AUTOSAR XML (schema 4-2-1)
standard types defined: boolean, float32, uint8, boolean_CompuMethod, boolean_DataConstr, float32_DataConstr, uint8_DataConstr
package /ComponentTypes
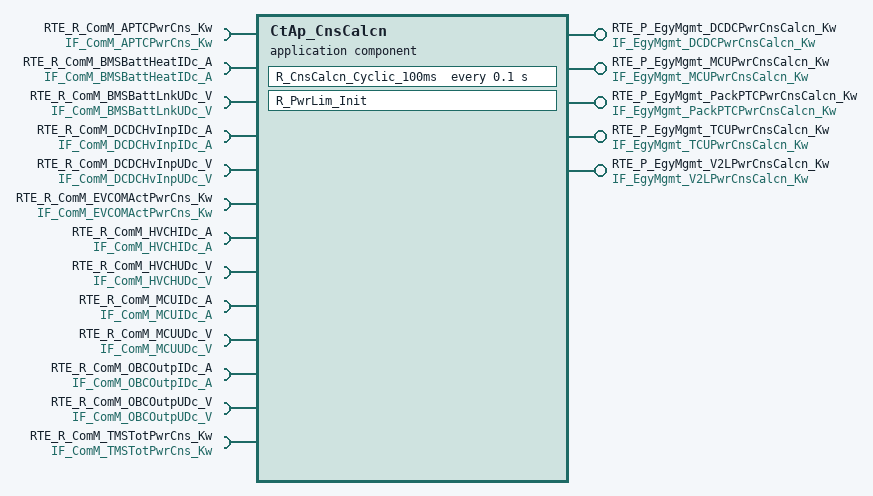
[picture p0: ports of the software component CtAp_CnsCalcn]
  application sw component type CtAp_CnsCalcn
    5 x provide port:
      RTE_P_EgyMgmt_DCDCPwrCnsCalcn_Kw: nonqueued-sender-com-spec{data-element=tec_EgyMgmt_DCDCPwrCnsCalcn_Kw, init-value=0}, provided-interface=IF_EgyMgmt_DCDCPwrCnsCalcn_Kw
      RTE_P_EgyMgmt_MCUPwrCnsCalcn_Kw: nonqueued-sender-com-spec{data-element=tec_EgyMgmt_MCUPwrCnsCalcn_Kw, init-value=0}, provided-interface=IF_EgyMgmt_MCUPwrCnsCalcn_Kw
      RTE_P_EgyMgmt_PackPTCPwrCnsCalcn_Kw: nonqueued-sender-com-spec{data-element=tec_EgyMgmt_PackPTCPwrCnsCalcn_Kw, init-value=0}, provided-interface=IF_EgyMgmt_PackPTCPwrCnsCalcn_Kw
      RTE_P_EgyMgmt_TCUPwrCnsCalcn_Kw: nonqueued-sender-com-spec{data-element=tec_EgyMgmt_TCUPwrCnsCalcn_Kw, init-value=0}, provided-interface=IF_EgyMgmt_TCUPwrCnsCalcn_Kw
      RTE_P_EgyMgmt_V2LPwrCnsCalcn_Kw: nonqueued-sender-com-spec{data-element=IF_EgyMgmt_V2LPwrCnsCalcn_Kw, init-value=0}, provided-interface=IF_EgyMgmt_V2LPwrCnsCalcn_Kw
    13 x require port:
      RTE_R_ComM_APTCPwrCns_Kw: nonqueued-receiver-com-spec{data-element=tec_ComM_APTCPwrCns_Kw, filter=data-filter-type=ALWAYS, init-value=0}, required-interface=IF_ComM_APTCPwrCns_Kw
      RTE_R_ComM_BMSBattHeatIDc_A: nonqueued-receiver-com-spec{data-element=tec_ComM_BMSBattHeatIDc_A, filter=data-filter-type=ALWAYS, init-value=0}, required-interface=IF_ComM_BMSBattHeatIDc_A
      RTE_R_ComM_BMSBattLnkUDc_V: nonqueued-receiver-com-spec{data-element=tec_ComM_BMSBattLnkUDc_V, filter=data-filter-type=ALWAYS, init-value=0}, required-interface=IF_ComM_BMSBattLnkUDc_V
      RTE_R_ComM_DCDCHvInpIDc_A: nonqueued-receiver-com-spec{data-element=tec_ComM_DCDCHvInpIDc_A, filter=data-filter-type=ALWAYS, init-value=0}, required-interface=IF_ComM_DCDCHvInpIDc_A
      RTE_R_ComM_DCDCHvInpUDc_V: nonqueued-receiver-com-spec{data-element=tec_ComM_DCDCHvInpUDc_V, filter=data-filter-type=ALWAYS, init-value=0}, required-interface=IF_ComM_DCDCHvInpUDc_V
      RTE_R_ComM_EVCOMActPwrCns_Kw: nonqueued-receiver-com-spec{data-element=tec_ComM_EVCOMActPwrCns_Kw, filter=data-filter-type=ALWAYS, init-value=0}, required-interface=IF_ComM_EVCOMActPwrCns_Kw
      RTE_R_ComM_HVCHIDc_A: nonqueued-receiver-com-spec{data-element=tec_ComM_HVCHIDc_A, filter=data-filter-type=ALWAYS, init-value=0}, required-interface=IF_ComM_HVCHIDc_A
      RTE_R_ComM_HVCHUDc_V: nonqueued-receiver-com-spec{data-element=tec_ComM_HVCHUDc_V, filter=data-filter-type=ALWAYS, init-value=0}, required-interface=IF_ComM_HVCHUDc_V
      RTE_R_ComM_MCUIDc_A: nonqueued-receiver-com-spec{data-element=tec_ComM_MCUIDc_A, filter=data-filter-type=ALWAYS, init-value=0}, required-interface=IF_ComM_MCUIDc_A
      RTE_R_ComM_MCUUDc_V: nonqueued-receiver-com-spec{data-element=tec_ComM_MCUUDc_V, filter=data-filter-type=ALWAYS, init-value=0}, required-interface=IF_ComM_MCUUDc_V
      RTE_R_ComM_OBCOutpIDc_A: nonqueued-receiver-com-spec{data-element=tec_ComM_OBCOutpIDc_A, filter=data-filter-type=ALWAYS, init-value=0}, required-interface=IF_ComM_OBCOutpIDc_A
      RTE_R_ComM_OBCOutpUDc_V: nonqueued-receiver-com-spec{data-element=tec_ComM_OBCOutpUDc_V, filter=data-filter-type=ALWAYS, init-value=0}, required-interface=IF_ComM_OBCOutpUDc_V
      RTE_R_ComM_TMSTotPwrCns_Kw: nonqueued-receiver-com-spec{data-element=tec_ComM_TMSTotPwrCns_Kw, filter=data-filter-type=ALWAYS, init-value=0}, required-interface=IF_ComM_TMSTotPwrCns_Kw
    behavior CtAp_CnsCalcn_InternalBehavior
      timing event TMT_R_CnsCalcn_Cyclic_100ms: start-on-event=R_CnsCalcn_Cyclic_100ms, period=0.1
      init event CtAp_PwrLim_InitEvent: start-on-event=CtAp_CnsCalcn_InternalBehavior/R_PwrLim_Init
      runnable R_CnsCalcn_Cyclic_100ms
        data-receive-point-by-arguments:
          13 x access:
            REC_RTE_R_ComM_APTCPwrCns_Kw_tec_ComM_APTCPwrCns_Kw: accessed-variable=RTE_R_ComM_APTCPwrCns_Kw.tec_ComM_APTCPwrCns_Kw
            REC_RTE_R_ComM_BMSBattHeatIDc_A_tec_ComM_BMSBattHeatIDc_A: accessed-variable=RTE_R_ComM_BMSBattHeatIDc_A.tec_ComM_BMSBattHeatIDc_A
            REC_RTE_R_ComM_BMSBattLnkUDc_V_tec_ComM_BMSBattLnkUDc_V: accessed-variable=RTE_R_ComM_BMSBattLnkUDc_V.tec_ComM_BMSBattLnkUDc_V
            REC_RTE_R_ComM_DCDCHvInpIDc_A_tec_ComM_DCDCHvInpIDc_A: accessed-variable=RTE_R_ComM_DCDCHvInpIDc_A.tec_ComM_DCDCHvInpIDc_A
            REC_RTE_R_ComM_DCDCHvInpUDc_V_tec_ComM_DCDCHvInpUDc_V: accessed-variable=RTE_R_ComM_DCDCHvInpUDc_V.tec_ComM_DCDCHvInpUDc_V
            REC_RTE_R_ComM_EVCOMActPwrCns_Kw_tec_ComM_EVCOMActPwrCns_Kw: accessed-variable=RTE_R_ComM_EVCOMActPwrCns_Kw.tec_ComM_EVCOMActPwrCns_Kw
            REC_RTE_R_ComM_HVCHIDc_A_tec_ComM_HVCHIDc_A: accessed-variable=RTE_R_ComM_HVCHIDc_A.tec_ComM_HVCHIDc_A
            REC_RTE_R_ComM_HVCHUDc_V_tec_ComM_HVCHUDc_V: accessed-variable=RTE_R_ComM_HVCHUDc_V.tec_ComM_HVCHUDc_V
            REC_RTE_R_ComM_MCUIDc_A_tec_ComM_MCUIDc_A: accessed-variable=RTE_R_ComM_MCUIDc_A.tec_ComM_MCUIDc_A
            REC_RTE_R_ComM_MCUUDc_V_tec_ComM_MCUUDc_V: accessed-variable=RTE_R_ComM_MCUUDc_V.tec_ComM_MCUUDc_V
            REC_RTE_R_ComM_OBCOutpIDc_A_tec_ComM_OBCOutpIDc_A: accessed-variable=RTE_R_ComM_OBCOutpIDc_A.tec_ComM_OBCOutpIDc_A
            REC_RTE_R_ComM_OBCOutpUDc_V_tec_ComM_OBCOutpUDc_V: accessed-variable=RTE_R_ComM_OBCOutpUDc_V.tec_ComM_OBCOutpUDc_V
            REC_RTE_R_ComM_TMSTotPwrCns_Kw_tec_ComM_TMSTotPwrCns_Kw: accessed-variable=RTE_R_ComM_TMSTotPwrCns_Kw.tec_ComM_TMSTotPwrCns_Kw
        data-send-points:
          5 x access:
            SEND_RTE_P_EgyMgmt_DCDCPwrCnsCalcn_Kw_tec_EgyMgmt_DCDCPwrCnsCalcn_Kw: accessed-variable=RTE_P_EgyMgmt_DCDCPwrCnsCalcn_Kw.tec_EgyMgmt_DCDCPwrCnsCalcn_Kw
            SEND_RTE_P_EgyMgmt_MCUPwrCnsCalcn_Kw_tec_EgyMgmt_MCUPwrCnsCalcn_Kw: accessed-variable=RTE_P_EgyMgmt_MCUPwrCnsCalcn_Kw.tec_EgyMgmt_MCUPwrCnsCalcn_Kw
            SEND_RTE_P_EgyMgmt_PackPTCPwrCnsCalcn_Kw_tec_EgyMgmt_PackPTCPwrCnsCalcn_Kw: accessed-variable=RTE_P_EgyMgmt_PackPTCPwrCnsCalcn_Kw.tec_EgyMgmt_PackPTCPwrCnsCalcn_Kw
            SEND_RTE_P_EgyMgmt_TCUPwrCnsCalcn_Kw_tec_EgyMgmt_TCUPwrCnsCalcn_Kw: accessed-variable=RTE_P_EgyMgmt_TCUPwrCnsCalcn_Kw.tec_EgyMgmt_TCUPwrCnsCalcn_Kw
            SEND_RTE_P_EgyMgmt_V2LPwrCnsCalcn_Kw_IF_EgyMgmt_V2LPwrCnsCalcn_Kw: accessed-variable=RTE_P_EgyMgmt_V2LPwrCnsCalcn_Kw.IF_EgyMgmt_V2LPwrCnsCalcn_Kw
      runnable R_PwrLim_Init
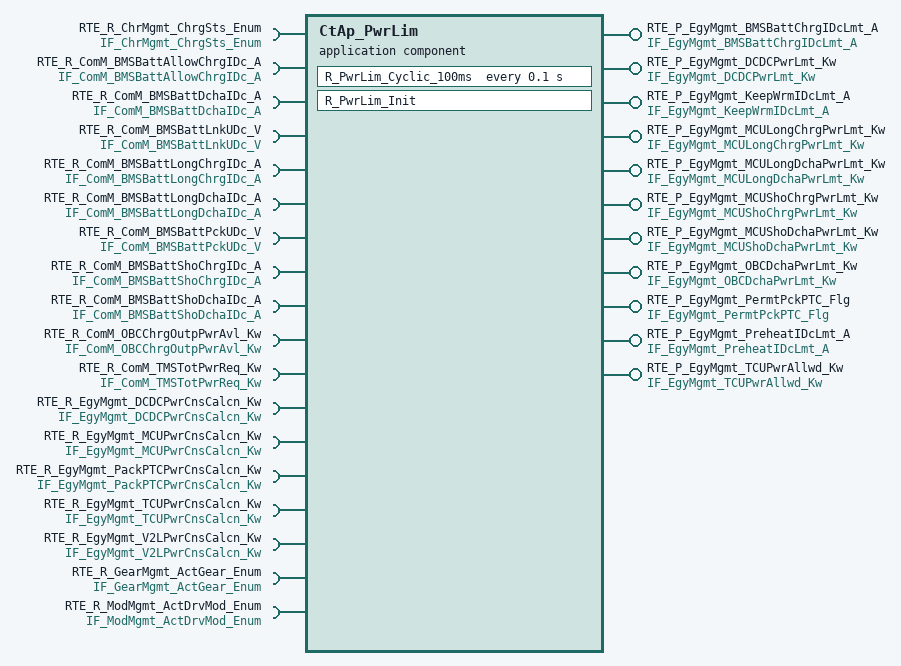
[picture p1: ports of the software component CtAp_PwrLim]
  application sw component type CtAp_PwrLim
    11 x provide port:
      RTE_P_EgyMgmt_BMSBattChrgIDcLmt_A: nonqueued-sender-com-spec{data-element=tec_EgyMgmt_BMSBattChrgIDcLmt_A, init-value=0}, provided-interface=IF_EgyMgmt_BMSBattChrgIDcLmt_A
      RTE_P_EgyMgmt_DCDCPwrLmt_Kw: nonqueued-sender-com-spec{data-element=tec_EgyMgmt_DCDCPwrLmt_Kw, init-value=0}, provided-interface=IF_EgyMgmt_DCDCPwrLmt_Kw
      RTE_P_EgyMgmt_KeepWrmIDcLmt_A: nonqueued-sender-com-spec{data-element=tec_EgyMgmt_KeepWrmIDcLmt_A, init-value=0}, provided-interface=IF_EgyMgmt_KeepWrmIDcLmt_A
      RTE_P_EgyMgmt_MCULongChrgPwrLmt_Kw: nonqueued-sender-com-spec{data-element=tec_EgyMgmt_MCULongChrgPwrLmt_Kw, init-value=0}, provided-interface=IF_EgyMgmt_MCULongChrgPwrLmt_Kw
      RTE_P_EgyMgmt_MCULongDchaPwrLmt_Kw: nonqueued-sender-com-spec{data-element=tec_EgyMgmt_MCULongDchaPwrLmt_Kw, init-value=0}, provided-interface=IF_EgyMgmt_MCULongDchaPwrLmt_Kw
      RTE_P_EgyMgmt_MCUShoChrgPwrLmt_Kw: nonqueued-sender-com-spec{data-element=tec_EgyMgmt_MCUShoChrgPwrLmt_Kw, init-value=0}, provided-interface=IF_EgyMgmt_MCUShoChrgPwrLmt_Kw
      RTE_P_EgyMgmt_MCUShoDchaPwrLmt_Kw: nonqueued-sender-com-spec{data-element=tec_EgyMgmt_MCUShoDchaPwrLmt_Kw, init-value=0}, provided-interface=IF_EgyMgmt_MCUShoDchaPwrLmt_Kw
      RTE_P_EgyMgmt_OBCDchaPwrLmt_Kw: nonqueued-sender-com-spec{data-element=tec_EgyMgmt_OBCDchaPwrLmt_Kw, init-value=0}, provided-interface=IF_EgyMgmt_OBCDchaPwrLmt_Kw
      RTE_P_EgyMgmt_PermtPckPTC_Flg: nonqueued-sender-com-spec{data-element=tec_EgyMgmt_PermtPckPTC_Flg, init-value=0}, provided-interface=IF_EgyMgmt_PermtPckPTC_Flg
      RTE_P_EgyMgmt_PreheatIDcLmt_A: nonqueued-sender-com-spec{data-element=tec_EgyMgmt_PreheatIDcLmt_A, init-value=0}, provided-interface=IF_EgyMgmt_PreheatIDcLmt_A
      RTE_P_EgyMgmt_TCUPwrAllwd_Kw: nonqueued-sender-com-spec{data-element=tec_EgyMgmt_TCUPwrAllwd_Kw, init-value=0}, provided-interface=IF_EgyMgmt_TCUPwrAllwd_Kw
    18 x require port:
      RTE_R_ChrMgmt_ChrgSts_Enum: nonqueued-receiver-com-spec{data-element=tec_ChrMgmt_ChrgSts_Enum, filter=data-filter-type=ALWAYS, init-value=0}, required-interface=IF_ChrMgmt_ChrgSts_Enum
      RTE_R_ComM_BMSBattAllowChrgIDc_A: nonqueued-receiver-com-spec{data-element=tec_ComM_BMSBattAllowChrgIDc_A, filter=data-filter-type=ALWAYS, init-value=0}, required-interface=IF_ComM_BMSBattAllowChrgIDc_A
      RTE_R_ComM_BMSBattDchaIDc_A: nonqueued-receiver-com-spec{data-element=tec_ComM_BMSBattDchaIDc_A, filter=data-filter-type=ALWAYS, init-value=0}, required-interface=IF_ComM_BMSBattDchaIDc_A
      RTE_R_ComM_BMSBattLnkUDc_V: nonqueued-receiver-com-spec{data-element=tec_ComM_BMSBattLnkUDc_V, filter=data-filter-type=ALWAYS, init-value=0}, required-interface=IF_ComM_BMSBattLnkUDc_V
      RTE_R_ComM_BMSBattLongChrgIDc_A: nonqueued-receiver-com-spec{data-element=tec_ComM_BMSBattLongChrgIDc_A, filter=data-filter-type=ALWAYS, init-value=0}, required-interface=IF_ComM_BMSBattLongChrgIDc_A
      RTE_R_ComM_BMSBattLongDchaIDc_A: nonqueued-receiver-com-spec{data-element=tec_ComM_BMSBattLongDchaIDc_A, filter=data-filter-type=ALWAYS, init-value=0}, required-interface=IF_ComM_BMSBattLongDchaIDc_A
      RTE_R_ComM_BMSBattPckUDc_V: nonqueued-receiver-com-spec{data-element=tec_ComM_BMSBattPckUDc_V, filter=data-filter-type=ALWAYS, init-value=0}, required-interface=IF_ComM_BMSBattPckUDc_V
      RTE_R_ComM_BMSBattShoChrgIDc_A: nonqueued-receiver-com-spec{data-element=tec_ComM_BMSBattShoChrgIDc_A, filter=data-filter-type=ALWAYS, init-value=0}, required-interface=IF_ComM_BMSBattShoChrgIDc_A
      RTE_R_ComM_BMSBattShoDchaIDc_A: nonqueued-receiver-com-spec{data-element=tec_ComM_BMSBattShoDchaIDc_A, filter=data-filter-type=ALWAYS, init-value=0}, required-interface=IF_ComM_BMSBattShoDchaIDc_A
      RTE_R_ComM_OBCChrgOutpPwrAvl_Kw: nonqueued-receiver-com-spec{data-element=tec_ComM_OBCChrgOutpPwrAvl_Kw, filter=data-filter-type=ALWAYS, init-value=0}, required-interface=IF_ComM_OBCChrgOutpPwrAvl_Kw
      RTE_R_ComM_TMSTotPwrReq_Kw: nonqueued-receiver-com-spec{data-element=tec_ComM_TMSTotPwrReq_Kw, filter=data-filter-type=ALWAYS, init-value=0}, required-interface=IF_ComM_TMSTotPwrReq_Kw
      RTE_R_EgyMgmt_DCDCPwrCnsCalcn_Kw: nonqueued-receiver-com-spec{data-element=tec_EgyMgmt_DCDCPwrCnsCalcn_Kw, filter=data-filter-type=ALWAYS, init-value=0}, required-interface=IF_EgyMgmt_DCDCPwrCnsCalcn_Kw
      RTE_R_EgyMgmt_MCUPwrCnsCalcn_Kw: nonqueued-receiver-com-spec{data-element=tec_EgyMgmt_MCUPwrCnsCalcn_Kw, filter=data-filter-type=ALWAYS, init-value=0}, required-interface=IF_EgyMgmt_MCUPwrCnsCalcn_Kw
      RTE_R_EgyMgmt_PackPTCPwrCnsCalcn_Kw: nonqueued-receiver-com-spec{data-element=tec_EgyMgmt_PackPTCPwrCnsCalcn_Kw, filter=data-filter-type=ALWAYS, init-value=0}, required-interface=IF_EgyMgmt_PackPTCPwrCnsCalcn_Kw
      RTE_R_EgyMgmt_TCUPwrCnsCalcn_Kw: nonqueued-receiver-com-spec{data-element=tec_EgyMgmt_TCUPwrCnsCalcn_Kw, filter=data-filter-type=ALWAYS, init-value=0}, required-interface=IF_EgyMgmt_TCUPwrCnsCalcn_Kw
      RTE_R_EgyMgmt_V2LPwrCnsCalcn_Kw: nonqueued-receiver-com-spec{data-element=IF_EgyMgmt_V2LPwrCnsCalcn_Kw, filter=data-filter-type=ALWAYS, init-value=0}, required-interface=IF_EgyMgmt_V2LPwrCnsCalcn_Kw
      RTE_R_GearMgmt_ActGear_Enum: nonqueued-receiver-com-spec{data-element=tec_GearMgmt_ActGear_Enum, filter=data-filter-type=ALWAYS, init-value=0}, required-interface=IF_GearMgmt_ActGear_Enum
      RTE_R_ModMgmt_ActDrvMod_Enum: nonqueued-receiver-com-spec{data-element=tec_ModMgmt_ActDrvMod_Enum, filter=data-filter-type=ALWAYS, init-value=0}, required-interface=IF_ModMgmt_ActDrvMod_Enum
    behavior CtAp_PwrLim_InternalBehavior
      timing event TMT_R_PwrLim_Cyclic_100ms: start-on-event=R_PwrLim_Cyclic_100ms, period=0.1
      init event CtAp_PwrLim_InitEvent: start-on-event=CtAp_PwrLim_InternalBehavior/R_PwrLim_Init
      runnable R_PwrLim_Cyclic_100ms
        data-receive-point-by-arguments:
          18 x access:
            REC_RTE_R_ChrMgmt_ChrgSts_Enum_tec_ChrMgmt_ChrgSts_Enum: accessed-variable=RTE_R_ChrMgmt_ChrgSts_Enum.tec_ChrMgmt_ChrgSts_Enum
            REC_RTE_R_ComM_BMSBattAllowChrgIDc_A_tec_ComM_BMSBattAllowChrgIDc_A: accessed-variable=RTE_R_ComM_BMSBattAllowChrgIDc_A.tec_ComM_BMSBattAllowChrgIDc_A
            REC_RTE_R_ComM_BMSBattDchaIDc_A_tec_ComM_BMSBattDchaIDc_A: accessed-variable=RTE_R_ComM_BMSBattDchaIDc_A.tec_ComM_BMSBattDchaIDc_A
            REC_RTE_R_ComM_BMSBattLnkUDc_V_tec_ComM_BMSBattLnkUDc_V: accessed-variable=RTE_R_ComM_BMSBattLnkUDc_V.tec_ComM_BMSBattLnkUDc_V
            REC_RTE_R_ComM_BMSBattLongChrgIDc_A_tec_ComM_BMSBattLongChrgIDc_A: accessed-variable=RTE_R_ComM_BMSBattLongChrgIDc_A.tec_ComM_BMSBattLongChrgIDc_A
            REC_RTE_R_ComM_BMSBattLongDchaIDc_A_tec_ComM_BMSBattLongDchaIDc_A: accessed-variable=RTE_R_ComM_BMSBattLongDchaIDc_A.tec_ComM_BMSBattLongDchaIDc_A
            REC_RTE_R_ComM_BMSBattPckUDc_V_tec_ComM_BMSBattPckUDc_V: accessed-variable=RTE_R_ComM_BMSBattPckUDc_V.tec_ComM_BMSBattPckUDc_V
            REC_RTE_R_ComM_BMSBattShoChrgIDc_A_tec_ComM_BMSBattShoChrgIDc_A: accessed-variable=RTE_R_ComM_BMSBattShoChrgIDc_A.tec_ComM_BMSBattShoChrgIDc_A
            REC_RTE_R_ComM_BMSBattShoDchaIDc_A_tec_ComM_BMSBattShoDchaIDc_A: accessed-variable=RTE_R_ComM_BMSBattShoDchaIDc_A.tec_ComM_BMSBattShoDchaIDc_A
            REC_RTE_R_ComM_OBCChrgOutpPwrAvl_Kw_tec_ComM_OBCChrgOutpPwrAvl_Kw: accessed-variable=RTE_R_ComM_OBCChrgOutpPwrAvl_Kw.tec_ComM_OBCChrgOutpPwrAvl_Kw
            REC_RTE_R_ComM_TMSTotPwrReq_Kw_tec_ComM_TMSTotPwrReq_Kw: accessed-variable=RTE_R_ComM_TMSTotPwrReq_Kw.tec_ComM_TMSTotPwrReq_Kw
            REC_RTE_R_EgyMgmt_DCDCPwrCnsCalcn_Kw_tec_EgyMgmt_DCDCPwrCnsCalcn_Kw: accessed-variable=RTE_R_EgyMgmt_DCDCPwrCnsCalcn_Kw.tec_EgyMgmt_DCDCPwrCnsCalcn_Kw
            REC_RTE_R_EgyMgmt_MCUPwrCnsCalcn_Kw_tec_EgyMgmt_MCUPwrCnsCalcn_Kw: accessed-variable=RTE_R_EgyMgmt_MCUPwrCnsCalcn_Kw.tec_EgyMgmt_MCUPwrCnsCalcn_Kw
            REC_RTE_R_EgyMgmt_PackPTCPwrCnsCalcn_Kw_tec_EgyMgmt_PackPTCPwrCnsCalcn_Kw: accessed-variable=RTE_R_EgyMgmt_PackPTCPwrCnsCalcn_Kw.tec_EgyMgmt_PackPTCPwrCnsCalcn_Kw
            REC_RTE_R_EgyMgmt_TCUPwrCnsCalcn_Kw_tec_EgyMgmt_TCUPwrCnsCalcn_Kw: accessed-variable=RTE_R_EgyMgmt_TCUPwrCnsCalcn_Kw.tec_EgyMgmt_TCUPwrCnsCalcn_Kw
            REC_RTE_R_EgyMgmt_V2LPwrCnsCalcn_Kw_IF_EgyMgmt_V2LPwrCnsCalcn_Kw: accessed-variable=RTE_R_EgyMgmt_V2LPwrCnsCalcn_Kw.IF_EgyMgmt_V2LPwrCnsCalcn_Kw
            REC_RTE_R_GearMgmt_ActGear_Enum_tec_GearMgmt_ActGear_Enum: accessed-variable=RTE_R_GearMgmt_ActGear_Enum.tec_GearMgmt_ActGear_Enum
            REC_RTE_R_ModMgmt_ActDrvMod_Enum_tec_ModMgmt_ActDrvMod_Enum: accessed-variable=RTE_R_ModMgmt_ActDrvMod_Enum.tec_ModMgmt_ActDrvMod_Enum
        data-send-points:
          11 x access:
            SEND_RTE_P_EgyMgmt_BMSBattChrgIDcLmt_A_tec_EgyMgmt_BMSBattChrgIDcLmt_A: accessed-variable=RTE_P_EgyMgmt_BMSBattChrgIDcLmt_A.tec_EgyMgmt_BMSBattChrgIDcLmt_A
            SEND_RTE_P_EgyMgmt_DCDCPwrLmt_Kw_tec_EgyMgmt_DCDCPwrLmt_Kw: accessed-variable=RTE_P_EgyMgmt_DCDCPwrLmt_Kw.tec_EgyMgmt_DCDCPwrLmt_Kw
            SEND_RTE_P_EgyMgmt_KeepWrmIDcLmt_A_tec_EgyMgmt_KeepWrmIDcLmt_A: accessed-variable=RTE_P_EgyMgmt_KeepWrmIDcLmt_A.tec_EgyMgmt_KeepWrmIDcLmt_A
            SEND_RTE_P_EgyMgmt_MCULongChrgPwrLmt_Kw_tec_EgyMgmt_MCULongChrgPwrLmt_Kw: accessed-variable=RTE_P_EgyMgmt_MCULongChrgPwrLmt_Kw.tec_EgyMgmt_MCULongChrgPwrLmt_Kw
            SEND_RTE_P_EgyMgmt_MCULongDchaPwrLmt_Kw_tec_EgyMgmt_MCULongDchaPwrLmt_Kw: accessed-variable=RTE_P_EgyMgmt_MCULongDchaPwrLmt_Kw.tec_EgyMgmt_MCULongDchaPwrLmt_Kw
            SEND_RTE_P_EgyMgmt_MCUShoChrgPwrLmt_Kw_tec_EgyMgmt_MCUShoChrgPwrLmt_Kw: accessed-variable=RTE_P_EgyMgmt_MCUShoChrgPwrLmt_Kw.tec_EgyMgmt_MCUShoChrgPwrLmt_Kw
            SEND_RTE_P_EgyMgmt_MCUShoDchaPwrLmt_Kw_tec_EgyMgmt_MCUShoDchaPwrLmt_Kw: accessed-variable=RTE_P_EgyMgmt_MCUShoDchaPwrLmt_Kw.tec_EgyMgmt_MCUShoDchaPwrLmt_Kw
            SEND_RTE_P_EgyMgmt_OBCDchaPwrLmt_Kw_tec_EgyMgmt_OBCDchaPwrLmt_Kw: accessed-variable=RTE_P_EgyMgmt_OBCDchaPwrLmt_Kw.tec_EgyMgmt_OBCDchaPwrLmt_Kw
            SEND_RTE_P_EgyMgmt_PermtPckPTC_Flg_tec_EgyMgmt_PermtPckPTC_Flg: accessed-variable=RTE_P_EgyMgmt_PermtPckPTC_Flg.tec_EgyMgmt_PermtPckPTC_Flg
            SEND_RTE_P_EgyMgmt_PreheatIDcLmt_A_tec_EgyMgmt_PreheatIDcLmt_A: accessed-variable=RTE_P_EgyMgmt_PreheatIDcLmt_A.tec_EgyMgmt_PreheatIDcLmt_A
            SEND_RTE_P_EgyMgmt_TCUPwrAllwd_Kw_tec_EgyMgmt_TCUPwrAllwd_Kw: accessed-variable=RTE_P_EgyMgmt_TCUPwrAllwd_Kw.tec_EgyMgmt_TCUPwrAllwd_Kw
      runnable R_PwrLim_Init
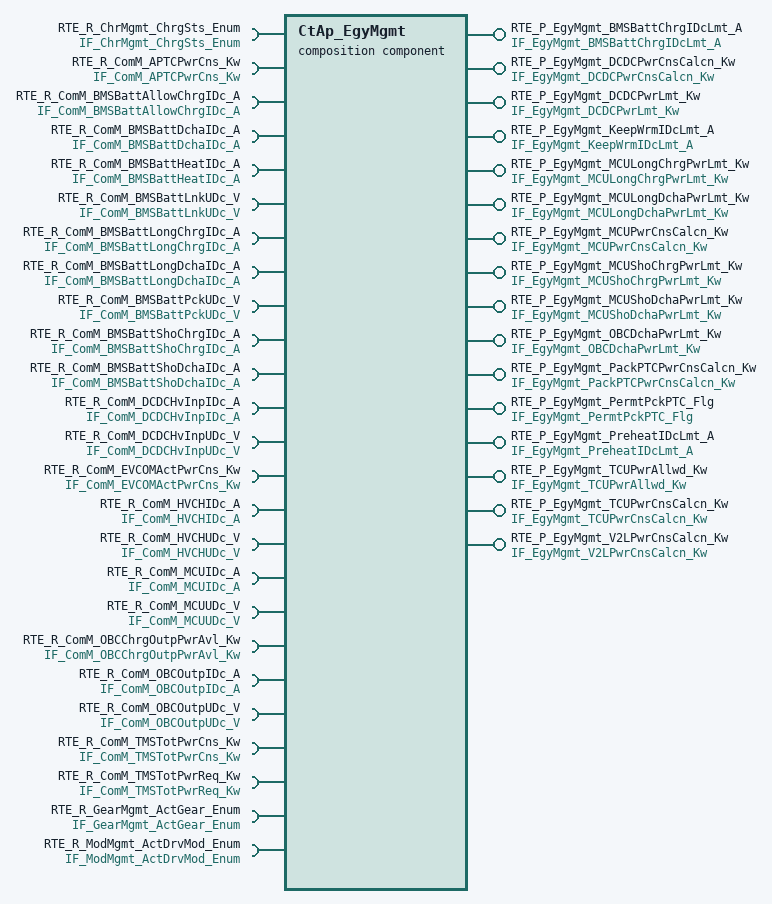
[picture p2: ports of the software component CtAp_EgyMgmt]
  composition sw component type CtAp_EgyMgmt
    16 x provide port:
      RTE_P_EgyMgmt_BMSBattChrgIDcLmt_A: nonqueued-sender-com-spec{data-element=tec_EgyMgmt_BMSBattChrgIDcLmt_A, init-value=0}, provided-interface=IF_EgyMgmt_BMSBattChrgIDcLmt_A
      RTE_P_EgyMgmt_DCDCPwrCnsCalcn_Kw: nonqueued-sender-com-spec{data-element=tec_EgyMgmt_DCDCPwrCnsCalcn_Kw, init-value=0}, provided-interface=IF_EgyMgmt_DCDCPwrCnsCalcn_Kw
      RTE_P_EgyMgmt_DCDCPwrLmt_Kw: nonqueued-sender-com-spec{data-element=tec_EgyMgmt_DCDCPwrLmt_Kw, init-value=0}, provided-interface=IF_EgyMgmt_DCDCPwrLmt_Kw
      RTE_P_EgyMgmt_KeepWrmIDcLmt_A: nonqueued-sender-com-spec{data-element=tec_EgyMgmt_KeepWrmIDcLmt_A, init-value=0}, provided-interface=IF_EgyMgmt_KeepWrmIDcLmt_A
      RTE_P_EgyMgmt_MCULongChrgPwrLmt_Kw: nonqueued-sender-com-spec{data-element=tec_EgyMgmt_MCULongChrgPwrLmt_Kw, init-value=0}, provided-interface=IF_EgyMgmt_MCULongChrgPwrLmt_Kw
      RTE_P_EgyMgmt_MCULongDchaPwrLmt_Kw: nonqueued-sender-com-spec{data-element=tec_EgyMgmt_MCULongDchaPwrLmt_Kw, init-value=0}, provided-interface=IF_EgyMgmt_MCULongDchaPwrLmt_Kw
      RTE_P_EgyMgmt_MCUPwrCnsCalcn_Kw: nonqueued-sender-com-spec{data-element=tec_EgyMgmt_MCUPwrCnsCalcn_Kw, init-value=0}, provided-interface=IF_EgyMgmt_MCUPwrCnsCalcn_Kw
      RTE_P_EgyMgmt_MCUShoChrgPwrLmt_Kw: nonqueued-sender-com-spec{data-element=tec_EgyMgmt_MCUShoChrgPwrLmt_Kw, init-value=0}, provided-interface=IF_EgyMgmt_MCUShoChrgPwrLmt_Kw
      RTE_P_EgyMgmt_MCUShoDchaPwrLmt_Kw: nonqueued-sender-com-spec{data-element=tec_EgyMgmt_MCUShoDchaPwrLmt_Kw, init-value=0}, provided-interface=IF_EgyMgmt_MCUShoDchaPwrLmt_Kw
      RTE_P_EgyMgmt_OBCDchaPwrLmt_Kw: nonqueued-sender-com-spec{data-element=tec_EgyMgmt_OBCDchaPwrLmt_Kw, init-value=0}, provided-interface=IF_EgyMgmt_OBCDchaPwrLmt_Kw
      RTE_P_EgyMgmt_PackPTCPwrCnsCalcn_Kw: nonqueued-sender-com-spec{data-element=tec_EgyMgmt_PackPTCPwrCnsCalcn_Kw, init-value=0}, provided-interface=IF_EgyMgmt_PackPTCPwrCnsCalcn_Kw
      RTE_P_EgyMgmt_PermtPckPTC_Flg: nonqueued-sender-com-spec{data-element=tec_EgyMgmt_PermtPckPTC_Flg, init-value=0}, provided-interface=IF_EgyMgmt_PermtPckPTC_Flg
      RTE_P_EgyMgmt_PreheatIDcLmt_A: nonqueued-sender-com-spec{data-element=tec_EgyMgmt_PreheatIDcLmt_A, init-value=0}, provided-interface=IF_EgyMgmt_PreheatIDcLmt_A
      RTE_P_EgyMgmt_TCUPwrAllwd_Kw: nonqueued-sender-com-spec{data-element=tec_EgyMgmt_TCUPwrAllwd_Kw, init-value=0}, provided-interface=IF_EgyMgmt_TCUPwrAllwd_Kw
      RTE_P_EgyMgmt_TCUPwrCnsCalcn_Kw: nonqueued-sender-com-spec{data-element=tec_EgyMgmt_TCUPwrCnsCalcn_Kw, init-value=0}, provided-interface=IF_EgyMgmt_TCUPwrCnsCalcn_Kw
      RTE_P_EgyMgmt_V2LPwrCnsCalcn_Kw: nonqueued-sender-com-spec{data-element=IF_EgyMgmt_V2LPwrCnsCalcn_Kw, init-value=0}, provided-interface=IF_EgyMgmt_V2LPwrCnsCalcn_Kw
    25 x require port:
      RTE_R_ChrMgmt_ChrgSts_Enum: nonqueued-receiver-com-spec{data-element=tec_ChrMgmt_ChrgSts_Enum, filter=data-filter-type=ALWAYS, init-value=0}, required-interface=IF_ChrMgmt_ChrgSts_Enum
      RTE_R_ComM_APTCPwrCns_Kw: nonqueued-receiver-com-spec{data-element=tec_ComM_APTCPwrCns_Kw, filter=data-filter-type=ALWAYS, init-value=0}, required-interface=IF_ComM_APTCPwrCns_Kw
      RTE_R_ComM_BMSBattAllowChrgIDc_A: nonqueued-receiver-com-spec{data-element=tec_ComM_BMSBattAllowChrgIDc_A, filter=data-filter-type=ALWAYS, init-value=0}, required-interface=IF_ComM_BMSBattAllowChrgIDc_A
      RTE_R_ComM_BMSBattDchaIDc_A: nonqueued-receiver-com-spec{data-element=tec_ComM_BMSBattDchaIDc_A, filter=data-filter-type=ALWAYS, init-value=0}, required-interface=IF_ComM_BMSBattDchaIDc_A
      RTE_R_ComM_BMSBattHeatIDc_A: nonqueued-receiver-com-spec{data-element=tec_ComM_BMSBattHeatIDc_A, filter=data-filter-type=ALWAYS, init-value=0}, required-interface=IF_ComM_BMSBattHeatIDc_A
      RTE_R_ComM_BMSBattLnkUDc_V: nonqueued-receiver-com-spec{data-element=tec_ComM_BMSBattLnkUDc_V, filter=data-filter-type=ALWAYS, init-value=0}, required-interface=IF_ComM_BMSBattLnkUDc_V
      RTE_R_ComM_BMSBattLongChrgIDc_A: nonqueued-receiver-com-spec{data-element=tec_ComM_BMSBattLongChrgIDc_A, filter=data-filter-type=ALWAYS, init-value=0}, required-interface=IF_ComM_BMSBattLongChrgIDc_A
      RTE_R_ComM_BMSBattLongDchaIDc_A: nonqueued-receiver-com-spec{data-element=tec_ComM_BMSBattLongDchaIDc_A, filter=data-filter-type=ALWAYS, init-value=0}, required-interface=IF_ComM_BMSBattLongDchaIDc_A
      RTE_R_ComM_BMSBattPckUDc_V: nonqueued-receiver-com-spec{data-element=tec_ComM_BMSBattPckUDc_V, filter=data-filter-type=ALWAYS, init-value=0}, required-interface=IF_ComM_BMSBattPckUDc_V
      RTE_R_ComM_BMSBattShoChrgIDc_A: nonqueued-receiver-com-spec{data-element=tec_ComM_BMSBattShoChrgIDc_A, filter=data-filter-type=ALWAYS, init-value=0}, required-interface=IF_ComM_BMSBattShoChrgIDc_A
      RTE_R_ComM_BMSBattShoDchaIDc_A: nonqueued-receiver-com-spec{data-element=tec_ComM_BMSBattShoDchaIDc_A, filter=data-filter-type=ALWAYS, init-value=0}, required-interface=IF_ComM_BMSBattShoDchaIDc_A
      RTE_R_ComM_DCDCHvInpIDc_A: nonqueued-receiver-com-spec{data-element=tec_ComM_DCDCHvInpIDc_A, filter=data-filter-type=ALWAYS, init-value=0}, required-interface=IF_ComM_DCDCHvInpIDc_A
      RTE_R_ComM_DCDCHvInpUDc_V: nonqueued-receiver-com-spec{data-element=tec_ComM_DCDCHvInpUDc_V, filter=data-filter-type=ALWAYS, init-value=0}, required-interface=IF_ComM_DCDCHvInpUDc_V
      RTE_R_ComM_EVCOMActPwrCns_Kw: nonqueued-receiver-com-spec{data-element=tec_ComM_EVCOMActPwrCns_Kw, filter=data-filter-type=ALWAYS, init-value=0}, required-interface=IF_ComM_EVCOMActPwrCns_Kw
      RTE_R_ComM_HVCHIDc_A: nonqueued-receiver-com-spec{data-element=tec_ComM_HVCHIDc_A, filter=data-filter-type=ALWAYS, init-value=0}, required-interface=IF_ComM_HVCHIDc_A
      RTE_R_ComM_HVCHUDc_V: nonqueued-receiver-com-spec{data-element=tec_ComM_HVCHUDc_V, filter=data-filter-type=ALWAYS, init-value=0}, required-interface=IF_ComM_HVCHUDc_V
      RTE_R_ComM_MCUIDc_A: nonqueued-receiver-com-spec{data-element=tec_ComM_MCUIDc_A, filter=data-filter-type=ALWAYS, init-value=0}, required-interface=IF_ComM_MCUIDc_A
      RTE_R_ComM_MCUUDc_V: nonqueued-receiver-com-spec{data-element=tec_ComM_MCUUDc_V, filter=data-filter-type=ALWAYS, init-value=0}, required-interface=IF_ComM_MCUUDc_V
      RTE_R_ComM_OBCChrgOutpPwrAvl_Kw: nonqueued-receiver-com-spec{data-element=tec_ComM_OBCChrgOutpPwrAvl_Kw, filter=data-filter-type=ALWAYS, init-value=0}, required-interface=IF_ComM_OBCChrgOutpPwrAvl_Kw
      RTE_R_ComM_OBCOutpIDc_A: nonqueued-receiver-com-spec{data-element=tec_ComM_OBCOutpIDc_A, filter=data-filter-type=ALWAYS, init-value=0}, required-interface=IF_ComM_OBCOutpIDc_A
      RTE_R_ComM_OBCOutpUDc_V: nonqueued-receiver-com-spec{data-element=tec_ComM_OBCOutpUDc_V, filter=data-filter-type=ALWAYS, init-value=0}, required-interface=IF_ComM_OBCOutpUDc_V
      RTE_R_ComM_TMSTotPwrCns_Kw: nonqueued-receiver-com-spec{data-element=tec_ComM_TMSTotPwrCns_Kw, filter=data-filter-type=ALWAYS, init-value=0}, required-interface=IF_ComM_TMSTotPwrCns_Kw
      RTE_R_ComM_TMSTotPwrReq_Kw: nonqueued-receiver-com-spec{data-element=tec_ComM_TMSTotPwrReq_Kw, filter=data-filter-type=ALWAYS, init-value=0}, required-interface=IF_ComM_TMSTotPwrReq_Kw
      RTE_R_GearMgmt_ActGear_Enum: nonqueued-receiver-com-spec{data-element=tec_GearMgmt_ActGear_Enum, filter=data-filter-type=ALWAYS, init-value=0}, required-interface=IF_GearMgmt_ActGear_Enum
      RTE_R_ModMgmt_ActDrvMod_Enum: nonqueued-receiver-com-spec{data-element=tec_ModMgmt_ActDrvMod_Enum, filter=data-filter-type=ALWAYS, init-value=0}, required-interface=IF_ModMgmt_ActDrvMod_Enum
    component CtAp_CnsCalcn: type=CtAp_CnsCalcn
    component CtAp_PwrLim: type=CtAp_PwrLim
    connect CtAp_CnsCalcn.RTE_P_EgyMgmt_DCDCPwrCnsCalcn_Kw -> CtAp_PwrLim.RTE_R_EgyMgmt_DCDCPwrCnsCalcn_Kw
    connect CtAp_CnsCalcn.RTE_P_EgyMgmt_MCUPwrCnsCalcn_Kw -> CtAp_PwrLim.RTE_R_EgyMgmt_MCUPwrCnsCalcn_Kw
    connect CtAp_CnsCalcn.RTE_P_EgyMgmt_PackPTCPwrCnsCalcn_Kw -> CtAp_PwrLim.RTE_R_EgyMgmt_PackPTCPwrCnsCalcn_Kw
    connect CtAp_CnsCalcn.RTE_P_EgyMgmt_TCUPwrCnsCalcn_Kw -> CtAp_PwrLim.RTE_R_EgyMgmt_TCUPwrCnsCalcn_Kw
    connect CtAp_CnsCalcn.RTE_P_EgyMgmt_V2LPwrCnsCalcn_Kw -> CtAp_PwrLim.RTE_R_EgyMgmt_V2LPwrCnsCalcn_Kw
    delegate CtAp_PwrLim.RTE_P_EgyMgmt_BMSBattChrgIDcLmt_A <-> outer port CtAp_EgyMgmt/RTE_P_EgyMgmt_BMSBattChrgIDcLmt_A
    delegate CtAp_CnsCalcn.RTE_P_EgyMgmt_DCDCPwrCnsCalcn_Kw <-> outer port CtAp_EgyMgmt/RTE_P_EgyMgmt_DCDCPwrCnsCalcn_Kw
    delegate CtAp_PwrLim.RTE_P_EgyMgmt_DCDCPwrLmt_Kw <-> outer port CtAp_EgyMgmt/RTE_P_EgyMgmt_DCDCPwrLmt_Kw
    delegate CtAp_PwrLim.RTE_P_EgyMgmt_KeepWrmIDcLmt_A <-> outer port CtAp_EgyMgmt/RTE_P_EgyMgmt_KeepWrmIDcLmt_A
    delegate CtAp_PwrLim.RTE_P_EgyMgmt_MCULongChrgPwrLmt_Kw <-> outer port CtAp_EgyMgmt/RTE_P_EgyMgmt_MCULongChrgPwrLmt_Kw
    delegate CtAp_PwrLim.RTE_P_EgyMgmt_MCULongDchaPwrLmt_Kw <-> outer port CtAp_EgyMgmt/RTE_P_EgyMgmt_MCULongDchaPwrLmt_Kw
    delegate CtAp_CnsCalcn.RTE_P_EgyMgmt_MCUPwrCnsCalcn_Kw <-> outer port CtAp_EgyMgmt/RTE_P_EgyMgmt_MCUPwrCnsCalcn_Kw
    delegate CtAp_PwrLim.RTE_P_EgyMgmt_MCUShoChrgPwrLmt_Kw <-> outer port CtAp_EgyMgmt/RTE_P_EgyMgmt_MCUShoChrgPwrLmt_Kw
    delegate CtAp_PwrLim.RTE_P_EgyMgmt_MCUShoDchaPwrLmt_Kw <-> outer port CtAp_EgyMgmt/RTE_P_EgyMgmt_MCUShoDchaPwrLmt_Kw
    delegate CtAp_PwrLim.RTE_P_EgyMgmt_OBCDchaPwrLmt_Kw <-> outer port CtAp_EgyMgmt/RTE_P_EgyMgmt_OBCDchaPwrLmt_Kw
    delegate CtAp_CnsCalcn.RTE_P_EgyMgmt_PackPTCPwrCnsCalcn_Kw <-> outer port CtAp_EgyMgmt/RTE_P_EgyMgmt_PackPTCPwrCnsCalcn_Kw
    delegate CtAp_PwrLim.RTE_P_EgyMgmt_PermtPckPTC_Flg <-> outer port CtAp_EgyMgmt/RTE_P_EgyMgmt_PermtPckPTC_Flg
    delegate CtAp_PwrLim.RTE_P_EgyMgmt_PreheatIDcLmt_A <-> outer port CtAp_EgyMgmt/RTE_P_EgyMgmt_PreheatIDcLmt_A
    delegate CtAp_PwrLim.RTE_P_EgyMgmt_TCUPwrAllwd_Kw <-> outer port CtAp_EgyMgmt/RTE_P_EgyMgmt_TCUPwrAllwd_Kw
    delegate CtAp_CnsCalcn.RTE_P_EgyMgmt_TCUPwrCnsCalcn_Kw <-> outer port CtAp_EgyMgmt/RTE_P_EgyMgmt_TCUPwrCnsCalcn_Kw
    delegate CtAp_CnsCalcn.RTE_P_EgyMgmt_V2LPwrCnsCalcn_Kw <-> outer port CtAp_EgyMgmt/RTE_P_EgyMgmt_V2LPwrCnsCalcn_Kw
    delegate CtAp_PwrLim.RTE_R_ChrMgmt_ChrgSts_Enum <-> outer port CtAp_EgyMgmt/RTE_R_ChrMgmt_ChrgSts_Enum
    delegate CtAp_CnsCalcn.RTE_R_ComM_APTCPwrCns_Kw <-> outer port CtAp_EgyMgmt/RTE_R_ComM_APTCPwrCns_Kw
    delegate CtAp_PwrLim.RTE_R_ComM_BMSBattAllowChrgIDc_A <-> outer port CtAp_EgyMgmt/RTE_R_ComM_BMSBattAllowChrgIDc_A
    delegate CtAp_PwrLim.RTE_R_ComM_BMSBattDchaIDc_A <-> outer port CtAp_EgyMgmt/RTE_R_ComM_BMSBattDchaIDc_A
    delegate CtAp_CnsCalcn.RTE_R_ComM_BMSBattHeatIDc_A <-> outer port CtAp_EgyMgmt/RTE_R_ComM_BMSBattHeatIDc_A
    delegate CtAp_CnsCalcn.RTE_R_ComM_BMSBattLnkUDc_V <-> outer port CtAp_EgyMgmt/RTE_R_ComM_BMSBattLnkUDc_V
    delegate CtAp_PwrLim.RTE_R_ComM_BMSBattLnkUDc_V <-> outer port CtAp_EgyMgmt/RTE_R_ComM_BMSBattLnkUDc_V
    delegate CtAp_PwrLim.RTE_R_ComM_BMSBattLongChrgIDc_A <-> outer port CtAp_EgyMgmt/RTE_R_ComM_BMSBattLongChrgIDc_A
    delegate CtAp_PwrLim.RTE_R_ComM_BMSBattLongDchaIDc_A <-> outer port CtAp_EgyMgmt/RTE_R_ComM_BMSBattLongDchaIDc_A
    delegate CtAp_PwrLim.RTE_R_ComM_BMSBattPckUDc_V <-> outer port CtAp_EgyMgmt/RTE_R_ComM_BMSBattPckUDc_V
    delegate CtAp_PwrLim.RTE_R_ComM_BMSBattShoChrgIDc_A <-> outer port CtAp_EgyMgmt/RTE_R_ComM_BMSBattShoChrgIDc_A
    delegate CtAp_PwrLim.RTE_R_ComM_BMSBattShoDchaIDc_A <-> outer port CtAp_EgyMgmt/RTE_R_ComM_BMSBattShoDchaIDc_A
    delegate CtAp_CnsCalcn.RTE_R_ComM_DCDCHvInpIDc_A <-> outer port CtAp_EgyMgmt/RTE_R_ComM_DCDCHvInpIDc_A
    delegate CtAp_CnsCalcn.RTE_R_ComM_DCDCHvInpUDc_V <-> outer port CtAp_EgyMgmt/RTE_R_ComM_DCDCHvInpUDc_V
    delegate CtAp_CnsCalcn.RTE_R_ComM_EVCOMActPwrCns_Kw <-> outer port CtAp_EgyMgmt/RTE_R_ComM_EVCOMActPwrCns_Kw
    delegate CtAp_CnsCalcn.RTE_R_ComM_HVCHIDc_A <-> outer port CtAp_EgyMgmt/RTE_R_ComM_HVCHIDc_A
    delegate CtAp_CnsCalcn.RTE_R_ComM_HVCHUDc_V <-> outer port CtAp_EgyMgmt/RTE_R_ComM_HVCHUDc_V
    delegate CtAp_CnsCalcn.RTE_R_ComM_MCUIDc_A <-> outer port CtAp_EgyMgmt/RTE_R_ComM_MCUIDc_A
    delegate CtAp_CnsCalcn.RTE_R_ComM_MCUUDc_V <-> outer port CtAp_EgyMgmt/RTE_R_ComM_MCUUDc_V
    delegate CtAp_PwrLim.RTE_R_ComM_OBCChrgOutpPwrAvl_Kw <-> outer port CtAp_EgyMgmt/RTE_R_ComM_OBCChrgOutpPwrAvl_Kw
    delegate CtAp_CnsCalcn.RTE_R_ComM_OBCOutpIDc_A <-> outer port CtAp_EgyMgmt/RTE_R_ComM_OBCOutpIDc_A
    delegate CtAp_CnsCalcn.RTE_R_ComM_OBCOutpUDc_V <-> outer port CtAp_EgyMgmt/RTE_R_ComM_OBCOutpUDc_V
    delegate CtAp_CnsCalcn.RTE_R_ComM_TMSTotPwrCns_Kw <-> outer port CtAp_EgyMgmt/RTE_R_ComM_TMSTotPwrCns_Kw
    delegate CtAp_PwrLim.RTE_R_ComM_TMSTotPwrReq_Kw <-> outer port CtAp_EgyMgmt/RTE_R_ComM_TMSTotPwrReq_Kw
    delegate CtAp_PwrLim.RTE_R_GearMgmt_ActGear_Enum <-> outer port CtAp_EgyMgmt/RTE_R_GearMgmt_ActGear_Enum
    delegate CtAp_PwrLim.RTE_R_ModMgmt_ActDrvMod_Enum <-> outer port CtAp_EgyMgmt/RTE_R_ModMgmt_ActDrvMod_Enum
  swc implementation CtAp_CnsCalcn_Implementation: behavior=CtAp_CnsCalcn_InternalBehavior
    code-descriptors:
      code Default: artifact-descriptors=autosar-engineering-object={short-label=Default, category=SWOBJ}
  swc implementation CtAp_PwrLim_Implementation: behavior=CtAp_PwrLim_InternalBehavior
    code-descriptors:
      code Default: artifact-descriptors=autosar-engineering-object={short-label=Default, category=SWOBJ}
package /PortInterfaces
  41 x sender receiver interface:
    IF_ChrMgmt_ChrgSts_Enum: invalidation-policy{data-element=tec_ChrMgmt_ChrgSts_Enum, handle-invalid=DONT-INVALIDATE}
      data tec_ChrMgmt_ChrgSts_Enum: type=uint8
    IF_ComM_APTCPwrCns_Kw: invalidation-policy{data-element=tec_ComM_APTCPwrCns_Kw, handle-invalid=DONT-INVALIDATE}
      data tec_ComM_APTCPwrCns_Kw: type=float32
    IF_ComM_BMSBattAllowChrgIDc_A: invalidation-policy{data-element=tec_ComM_BMSBattAllowChrgIDc_A, handle-invalid=DONT-INVALIDATE}
      data tec_ComM_BMSBattAllowChrgIDc_A: type=float32
    IF_ComM_BMSBattDchaIDc_A: invalidation-policy{data-element=tec_ComM_BMSBattDchaIDc_A, handle-invalid=DONT-INVALIDATE}
      data tec_ComM_BMSBattDchaIDc_A: type=float32
    IF_ComM_BMSBattHeatIDc_A: invalidation-policy{data-element=tec_ComM_BMSBattHeatIDc_A, handle-invalid=DONT-INVALIDATE}
      data tec_ComM_BMSBattHeatIDc_A: type=float32
    IF_ComM_BMSBattLnkUDc_V: invalidation-policy{data-element=tec_ComM_BMSBattLnkUDc_V, handle-invalid=DONT-INVALIDATE}
      data tec_ComM_BMSBattLnkUDc_V: type=float32
    IF_ComM_BMSBattLongChrgIDc_A: invalidation-policy{data-element=tec_ComM_BMSBattLongChrgIDc_A, handle-invalid=DONT-INVALIDATE}
      data tec_ComM_BMSBattLongChrgIDc_A: type=float32
    IF_ComM_BMSBattLongDchaIDc_A: invalidation-policy{data-element=tec_ComM_BMSBattLongDchaIDc_A, handle-invalid=DONT-INVALIDATE}
      data tec_ComM_BMSBattLongDchaIDc_A: type=float32
    IF_ComM_BMSBattPckUDc_V: invalidation-policy{data-element=tec_ComM_BMSBattPckUDc_V, handle-invalid=DONT-INVALIDATE}
      data tec_ComM_BMSBattPckUDc_V: type=float32
    IF_ComM_BMSBattShoChrgIDc_A: invalidation-policy{data-element=tec_ComM_BMSBattShoChrgIDc_A, handle-invalid=DONT-INVALIDATE}
      data tec_ComM_BMSBattShoChrgIDc_A: type=float32
    IF_ComM_BMSBattShoDchaIDc_A: invalidation-policy{data-element=tec_ComM_BMSBattShoDchaIDc_A, handle-invalid=DONT-INVALIDATE}
      data tec_ComM_BMSBattShoDchaIDc_A: type=float32
    IF_ComM_DCDCHvInpIDc_A: invalidation-policy{data-element=tec_ComM_DCDCHvInpIDc_A, handle-invalid=DONT-INVALIDATE}
      data tec_ComM_DCDCHvInpIDc_A: type=float32
    IF_ComM_DCDCHvInpUDc_V: invalidation-policy{data-element=tec_ComM_DCDCHvInpUDc_V, handle-invalid=DONT-INVALIDATE}
      data tec_ComM_DCDCHvInpUDc_V: type=float32
    IF_ComM_EVCOMActPwrCns_Kw: invalidation-policy{data-element=tec_ComM_EVCOMActPwrCns_Kw, handle-invalid=DONT-INVALIDATE}
      data tec_ComM_EVCOMActPwrCns_Kw: type=float32
    IF_ComM_HVCHIDc_A: invalidation-policy{data-element=tec_ComM_HVCHIDc_A, handle-invalid=DONT-INVALIDATE}
      data tec_ComM_HVCHIDc_A: type=float32
    IF_ComM_HVCHUDc_V: invalidation-policy{data-element=tec_ComM_HVCHUDc_V, handle-invalid=DONT-INVALIDATE}
      data tec_ComM_HVCHUDc_V: type=float32
    IF_ComM_MCUIDc_A: invalidation-policy{data-element=tec_ComM_MCUIDc_A, handle-invalid=DONT-INVALIDATE}
      data tec_ComM_MCUIDc_A: type=float32
    IF_ComM_MCUUDc_V: invalidation-policy{data-element=tec_ComM_MCUUDc_V, handle-invalid=DONT-INVALIDATE}
      data tec_ComM_MCUUDc_V: type=float32
    IF_ComM_OBCChrgOutpPwrAvl_Kw: invalidation-policy{data-element=tec_ComM_OBCChrgOutpPwrAvl_Kw, handle-invalid=DONT-INVALIDATE}
      data tec_ComM_OBCChrgOutpPwrAvl_Kw: type=float32
    IF_ComM_OBCOutpIDc_A: invalidation-policy{data-element=tec_ComM_OBCOutpIDc_A, handle-invalid=DONT-INVALIDATE}
      data tec_ComM_OBCOutpIDc_A: type=float32
    IF_ComM_OBCOutpUDc_V: invalidation-policy{data-element=tec_ComM_OBCOutpUDc_V, handle-invalid=DONT-INVALIDATE}
      data tec_ComM_OBCOutpUDc_V: type=float32
    IF_ComM_TMSTotPwrCns_Kw: invalidation-policy{data-element=tec_ComM_TMSTotPwrCns_Kw, handle-invalid=DONT-INVALIDATE}
      data tec_ComM_TMSTotPwrCns_Kw: type=float32
    IF_ComM_TMSTotPwrReq_Kw: invalidation-policy{data-element=tec_ComM_TMSTotPwrReq_Kw, handle-invalid=DONT-INVALIDATE}
      data tec_ComM_TMSTotPwrReq_Kw: type=float32
    IF_EgyMgmt_BMSBattChrgIDcLmt_A: invalidation-policy{data-element=tec_EgyMgmt_BMSBattChrgIDcLmt_A, handle-invalid=DONT-INVALIDATE}
      data tec_EgyMgmt_BMSBattChrgIDcLmt_A: type=float32
    IF_EgyMgmt_DCDCPwrCnsCalcn_Kw: invalidation-policy{data-element=tec_EgyMgmt_DCDCPwrCnsCalcn_Kw, handle-invalid=DONT-INVALIDATE}
      data tec_EgyMgmt_DCDCPwrCnsCalcn_Kw: type=float32
    IF_EgyMgmt_DCDCPwrLmt_Kw: invalidation-policy{data-element=tec_EgyMgmt_DCDCPwrLmt_Kw, handle-invalid=DONT-INVALIDATE}
      data tec_EgyMgmt_DCDCPwrLmt_Kw: type=float32
    IF_EgyMgmt_KeepWrmIDcLmt_A: invalidation-policy{data-element=tec_EgyMgmt_KeepWrmIDcLmt_A, handle-invalid=DONT-INVALIDATE}
      data tec_EgyMgmt_KeepWrmIDcLmt_A: type=float32
    IF_EgyMgmt_MCULongChrgPwrLmt_Kw: invalidation-policy{data-element=tec_EgyMgmt_MCULongChrgPwrLmt_Kw, handle-invalid=DONT-INVALIDATE}
      data tec_EgyMgmt_MCULongChrgPwrLmt_Kw: type=float32
    IF_EgyMgmt_MCULongDchaPwrLmt_Kw: invalidation-policy{data-element=tec_EgyMgmt_MCULongDchaPwrLmt_Kw, handle-invalid=DONT-INVALIDATE}
      data tec_EgyMgmt_MCULongDchaPwrLmt_Kw: type=float32
    IF_EgyMgmt_MCUPwrCnsCalcn_Kw: invalidation-policy{data-element=tec_EgyMgmt_MCUPwrCnsCalcn_Kw, handle-invalid=DONT-INVALIDATE}
      data tec_EgyMgmt_MCUPwrCnsCalcn_Kw: type=float32
    IF_EgyMgmt_MCUShoChrgPwrLmt_Kw: invalidation-policy{data-element=tec_EgyMgmt_MCUShoChrgPwrLmt_Kw, handle-invalid=DONT-INVALIDATE}
      data tec_EgyMgmt_MCUShoChrgPwrLmt_Kw: type=float32
    IF_EgyMgmt_MCUShoDchaPwrLmt_Kw: invalidation-policy{data-element=tec_EgyMgmt_MCUShoDchaPwrLmt_Kw, handle-invalid=DONT-INVALIDATE}
      data tec_EgyMgmt_MCUShoDchaPwrLmt_Kw: type=float32
    IF_EgyMgmt_OBCDchaPwrLmt_Kw: invalidation-policy{data-element=tec_EgyMgmt_OBCDchaPwrLmt_Kw, handle-invalid=DONT-INVALIDATE}
      data tec_EgyMgmt_OBCDchaPwrLmt_Kw: type=float32
    IF_EgyMgmt_PackPTCPwrCnsCalcn_Kw: invalidation-policy{data-element=tec_EgyMgmt_PackPTCPwrCnsCalcn_Kw, handle-invalid=DONT-INVALIDATE}
      data tec_EgyMgmt_PackPTCPwrCnsCalcn_Kw: type=float32
    IF_EgyMgmt_PermtPckPTC_Flg: invalidation-policy{data-element=tec_EgyMgmt_PermtPckPTC_Flg, handle-invalid=DONT-INVALIDATE}
      data tec_EgyMgmt_PermtPckPTC_Flg: type=boolean
    IF_EgyMgmt_PreheatIDcLmt_A: invalidation-policy{data-element=tec_EgyMgmt_PreheatIDcLmt_A, handle-invalid=DONT-INVALIDATE}
      data tec_EgyMgmt_PreheatIDcLmt_A: type=float32
    IF_EgyMgmt_TCUPwrAllwd_Kw: invalidation-policy{data-element=tec_EgyMgmt_TCUPwrAllwd_Kw, handle-invalid=DONT-INVALIDATE}
      data tec_EgyMgmt_TCUPwrAllwd_Kw: type=float32
    IF_EgyMgmt_TCUPwrCnsCalcn_Kw: invalidation-policy{data-element=tec_EgyMgmt_TCUPwrCnsCalcn_Kw, handle-invalid=DONT-INVALIDATE}
      data tec_EgyMgmt_TCUPwrCnsCalcn_Kw: type=float32
    IF_EgyMgmt_V2LPwrCnsCalcn_Kw: invalidation-policy{data-element=IF_EgyMgmt_V2LPwrCnsCalcn_Kw, handle-invalid=DONT-INVALIDATE}
      data IF_EgyMgmt_V2LPwrCnsCalcn_Kw: type=float32
    IF_GearMgmt_ActGear_Enum: invalidation-policy{data-element=tec_GearMgmt_ActGear_Enum, handle-invalid=DONT-INVALIDATE}
      data tec_GearMgmt_ActGear_Enum: type=uint8
    IF_ModMgmt_ActDrvMod_Enum: invalidation-policy{data-element=tec_ModMgmt_ActDrvMod_Enum, handle-invalid=DONT-INVALIDATE}
      data tec_ModMgmt_ActDrvMod_Enum: type=uint8
